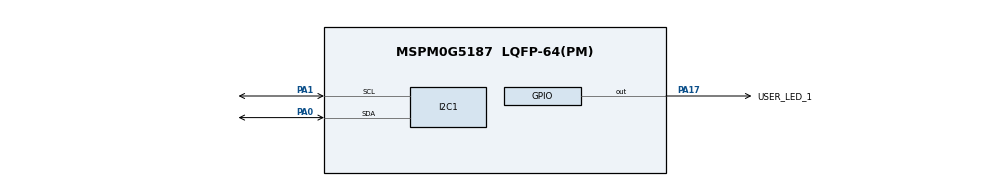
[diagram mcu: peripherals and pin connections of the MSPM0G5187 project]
//@cliArgs --device "MSPM0G518X" --package "LQFP-64(PM)" --part "Default"
//@v2CliArgs --device "MSPM0G5187" --package "LQFP-64(PM)"
// @cliArgs --board /ti/boards/LP_MSPM0G5187 --rtos nortos

/**
 * Import the modules used in this configuration.
 */
const GPIO   = scripting.addModule("/ti/driverlib/GPIO", {}, false);
const GPIO1  = GPIO.addInstance();
const I2C    = scripting.addModule("/ti/driverlib/I2C", {}, false);
const I2C1   = I2C.addInstance();
const SYSCTL = scripting.addModule("/ti/driverlib/SYSCTL");

/**
 * Write custom configuration values to the imported modules.
 */
GPIO1.$name                          = "GPIO_LEDS";
GPIO1.associatedPins[0].$name        = "USER_LED_1";
GPIO1.associatedPins[0].assignedPort = "PORTA";
GPIO1.associatedPins[0].assignedPin  = "17";
GPIO1.associatedPins[0].pin.$assign  = "PA17";

const Board = scripting.addModule("/ti/driverlib/Board", {}, false);
Board.configureUnused = true;

I2C1.basicControllerBusSpeed   = 400000;
I2C1.advControllerTXFIFOTRIG   = "ALMOST_EMPTY";
I2C1.basicTargetAddress        = 0x48;
I2C1.$name                     = "I2C";
I2C1.basicEnableTarget         = true;
I2C1.advTargetTXFIFOTRIG       = "ALMOST_EMPTY";
I2C1.intTarget                 = ["RXFIFO_TRIGGER","START","STOP"];
I2C1.advTargetTXEmptyEn        = true;
I2C1.peripheral.$assign        = "UC1";
I2C1.peripheral.sdaPin.$assign = "PA0";
I2C1.peripheral.sclPin.$assign = "PA1";

SYSCTL.powerPolicy = "STOP0";
SYSCTL.forceDefaultClkConfig = true;
SYSCTL.clockTreeEn  = true;
